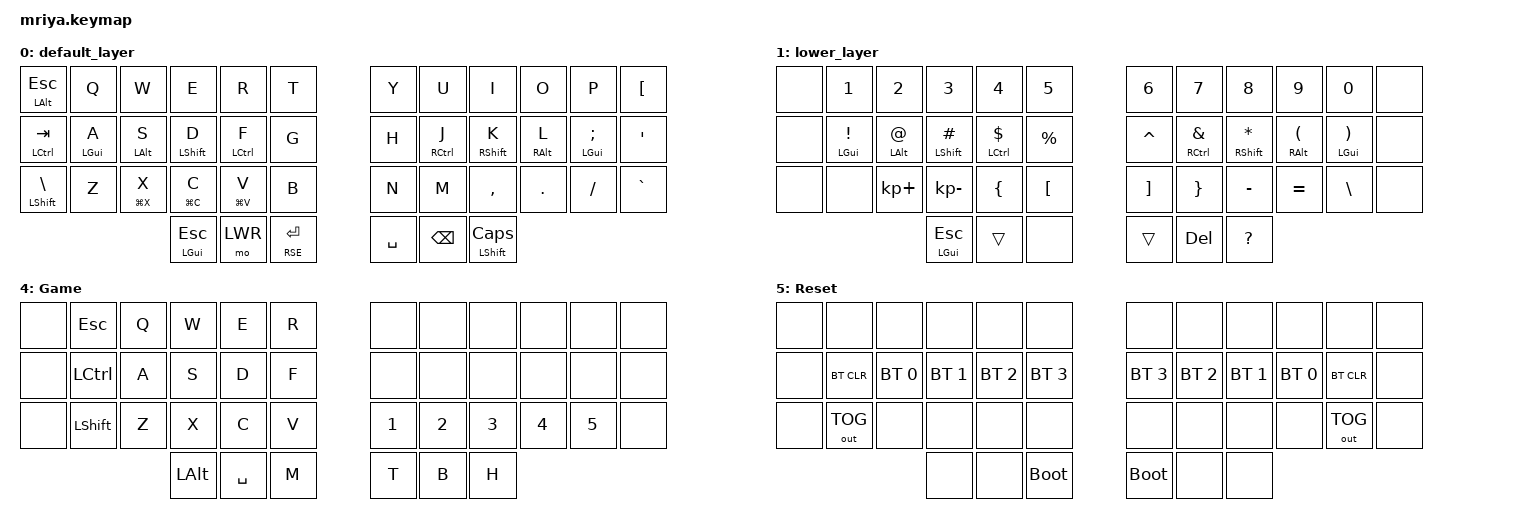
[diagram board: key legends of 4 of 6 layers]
#include <behaviors.dtsi>
#include <dt-bindings/zmk/bt.h>
#include <dt-bindings/zmk/keys.h>
#include <dt-bindings/zmk/outputs.h>

#define KEYS_L 0 1 2 3 4 5 12 13 14 15 16 17 24 25 26 27 28 29  
#define KEYS_R 6 7 8 9 10 11 18 19 20 21 22 23 30 31 32 33 34 35
#define THUMBS 36 37 38 39 40 41

#define DEF 0
#define LWR 1
#define RSE 2
#define FUNCTION 3
#define GAME 4
#define RESET 5

&mt {
  flavor = "tap-preferred";
};

&lt {
  flavor = "balanced";
  tapping-term-ms = <200>;
  quick-tap-ms = <175>;
};

/ {
  behaviors {
    hml: hml {
      compatible = "zmk,behavior-hold-tap";
      #binding-cells = <2>;
      flavor = "balanced";
      tapping-term-ms = <2000>;
      quick-tap-ms = <175>;
      require-prior-idle-ms = <250>;
      hold-trigger-key-positions = <KEYS_R THUMBS>;
      hold-trigger-on-release;
      bindings =
        <&kp>,
        <&kp>;
    };

    hmr: hmr {
      compatible = "zmk,behavior-hold-tap";
      #binding-cells = <2>;
      flavor = "balanced";
      tapping-term-ms = <2000>;
      quick-tap-ms = <175>;
      require-prior-idle-ms = <250>;
      hold-trigger-key-positions = <KEYS_L THUMBS>;
      hold-trigger-on-release;
      bindings =
        <&kp>,
        <&kp>;
    };

    hml_s: hml_s {
      compatible = "zmk,behavior-hold-tap";
      #binding-cells = <2>;
      flavor = "balanced";
      tapping-term-ms = <2000>;
      quick-tap-ms = <175>;
      require-prior-idle-ms = <0>;
      hold-trigger-key-positions = <KEYS_R THUMBS>;
      hold-trigger-on-release;
      bindings =
        <&kp>,
        <&kp>;
    };

    hmr_s: hmr_s {
      compatible = "zmk,behavior-hold-tap";
      #binding-cells = <2>;
      flavor = "balanced";
      tapping-term-ms = <2000>;
      quick-tap-ms = <175>;
      require-prior-idle-ms = <0>;
      hold-trigger-key-positions = <KEYS_L THUMBS>;
      hold-trigger-on-release;
      bindings =
        <&kp>,
        <&kp>;
    };
  };

  combos {
    compatible = "zmk,combos";
    timeout-ms = <20>;
    require-prior-idle-ms = <250>;

    combo_reset_layer_left {
      key-positions = <25 29>;
      bindings = <&to RESET>;
    };
    combo_reset_layer_right {
      key-positions = <30 34>;
      bindings = <&to RESET>;
    };
    combo_reset_central {
      key-positions = <32 33>;
      bindings = <&bootloader>;
      require-prior-idle-ms = <2000>;
    };
    combo_normal {
      key-positions = <8 9>;
      bindings = <&to DEF>;
    };
    combo_fn {
      key-positions = <32 33>;
      bindings = <&sl FUNCTION>;
    };
    combo_game {
      key-positions = <6 10>;
      bindings = <&to GAME>;
    };
    combo_esc {
      key-positions = <2 3>;
      bindings = <&kp ESCAPE>;
    };
    combo_tab {
      key-positions = <3 4>;
      bindings = <&kp TAB>;
      };
    combo_cdel {
      key-positions = <14 15>;
      bindings = <&kp LC(BACKSPACE)>;
    };
    combo_unlock {
      key-positions = <1 5>;
      bindings = <&studio_unlock>;
    };
    combo_term1 {
      key-positions = <25 26>;
      bindings = <&kp LG(BSLH)>;
    };
    combo_term2 {
      key-positions = <33 34>;
      bindings = <&kp LG(GRAVE)>;
    };
  };

  keymap {
    compatible = "zmk,keymap";

    default_layer {
      bindings = <
        &mt LALT ESC &kp Q       &kp W       &kp E           &kp R        &kp T          &kp Y     &kp U         &kp I        &kp O       &kp P &kp LBKT
        &mt LCTRL TAB &hml LGUI A &hml LALT S &hml LSHFT D    &hml LCTRL F &kp G          &kp H     &hmr RCTRL J  &hmr RSHFT K &hmr RALT L &hmr LGUI SEMI &kp SQT
        &mt LSHIFT BSLH &kp Z       &mt LG(X) X &mt LG(C) C     &mt LG(V) V  &kp B          &kp N     &kp M         &kp COMMA    &kp DOT     &kp FSLH &kp GRAVE
                                &mt LGUI ESCAPE &mo LWR      &lt RSE RET    &kp SPACE &kp BACKSPACE &mt LSHFT CAPS
      >;      
    };

    lower_layer {
      bindings = <
        &none &kp N1            &kp N2          &kp N3             &kp N4                   &kp N5                     &kp N6              &kp N7             &kp N8               &kp N9                        &kp N0              &none 
        &none &hml_s LGUI EXCL  &hml_s LALT AT  &hml_s LSHFT HASH  &hml_s LCTRL DOLLAR      &kp PERCENT                &kp CARET           &hmr_s RCTRL AMPS  &hmr_s RSHFT ASTRK   &hmr_s RALT LEFT_PARENTHESIS  &hmr_s LGUI RIGHT_PARENTHESIS &none 
        &none &none             &kp KP_PLUS     &kp KP_MINUS       &kp LEFT_BRACE           &kp LEFT_BRACKET           &kp RIGHT_BRACKET   &kp RIGHT_BRACE    &kp MINUS            &kp EQUAL                     &kp BSLH &none
                                          &mt LGUI ESCAPE    &trans                   &none                      &trans              &kp DEL            &kp QMARK
      >;
    };

    raise_layer {
      bindings = <
        &none &kp LS(LG(N4))  &kp LS(LC(LG(N4)))  &kp LS(LG(N5))  &kp PAGE_DOWN  &kp LBKT          &none                &kp PG_UP            &kp PG_DN            &kp HOME       &kp LBKT  &none 
        &none &none           &none               &none           &kp BSLH       &kp SQT           &kp LEFT             &kp DOWN             &kp UP_ARROW         &kp RIGHT      &kp SQT   &none 
        &none &none           &none               &none           &none          &kp GRAVE         &kp LC(LEFT_ARROW)   &kp LC(RIGHT_ARROW)  &kp LA(LEFT)         &kp LA(RIGHT)  &kp GRAVE &none 
                                            &kp LGUI        &none          &trans            &trans               &trans               &trans
      >;
    };

    Fun {
      bindings = <
        &none &kp F11 &kp F12 &none  &none  &kp LC(LA(DEL)) &none &none     &none     &none    &none         &trans   &none 
        &none &kp F6  &kp F7  &kp F8 &kp F9 &kp F10         &none &kp LCTRL &kp LSHFT &kp LALT &kp LGUI      &trans   &none 
        &none &kp F1  &kp F2  &kp F3 &kp F4 &kp F5          &none &none     &none     &none    &none         &trans   &none 
                        &none  &none  &none           &none &none &none
      >;
    };

    Game {
      bindings = <
        &none &kp ESCAPE &kp Q &kp W     &kp E     &kp R          &none  &none    &none    &none    &none &none 
        &none &kp LCTRL  &kp A &kp S     &kp D     &kp F          &none  &none    &none    &none    &none &none 
        &none &kp LSHIFT &kp Z &kp X     &kp C     &kp V          &kp N1 &kp N2   &kp N3   &kp N4   &kp N5 &none
                         &kp LALT  &kp SPACE &kp M          &kp T  &kp B    &kp H 
      >;
    };

    Reset {
      bindings = <
        &none &none        &none        &none        &none        &none                 &none        &none        &none        &none        &none     &none 
        &none &bt BT_CLR   &bt BT_SEL 0 &bt BT_SEL 1 &bt BT_SEL 2 &bt BT_SEL 3          &bt BT_SEL 3 &bt BT_SEL 2 &bt BT_SEL 1 &bt BT_SEL 0 &bt BT_CLR    &none 
        &none &out OUT_TOG &none        &none        &none        &none                 &none        &none        &none        &none        &out OUT_TOG &none 
                                  &none        &none        &bootloader           &bootloader  &none        &none               
      >;
    };
  };
};
